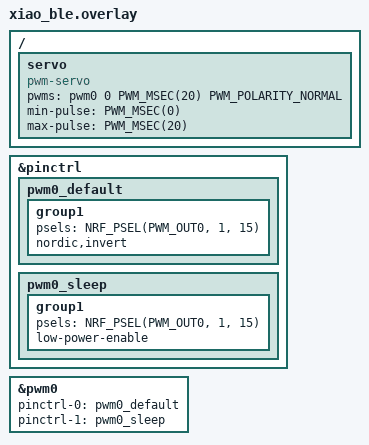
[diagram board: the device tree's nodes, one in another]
/ {
    // this section informs Zephyr that a servo (our vibrator) is connected to the board via PWM on
    // pwm0 (channel 1) with a 20 ms period, and it specifies the pulse width
    // range (0 to 20ms) that corresponds to the full range of possible voltages for controlling its speed.
    servo: servo {
        compatible = "pwm-servo";
        pwms = <&pwm0 0 PWM_MSEC(20) PWM_POLARITY_NORMAL>;
        min-pulse = <PWM_MSEC(0)>;
        max-pulse = <PWM_MSEC(20)>;
    };
};


// Define the PWM0 pins as 1.15 (Pin 10)
&pinctrl {
    pwm0_default: pwm0_default {
        group1 {
			psels = <NRF_PSEL(PWM_OUT0, 1, 15)>;
			nordic,invert;
		};
    };
    pwm0_sleep: pwm0_sleep {
		group1 {
			psels = <NRF_PSEL(PWM_OUT0, 1, 15)>;
			low-power-enable;
		};
	};
};


// Activate the PWM0
&pwm0 {
    status = "okay";
    pinctrl-0 = <&pwm0_default>;
    pinctrl-1 = <&pwm0_sleep>;
	pinctrl-names = "default", "sleep";

};
